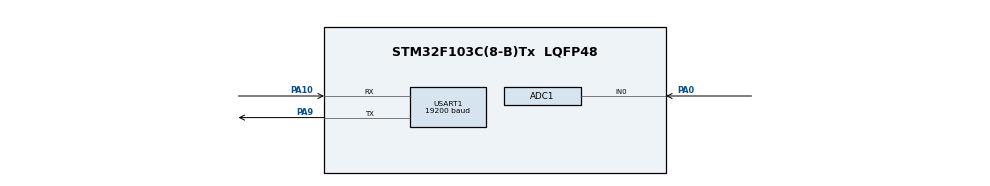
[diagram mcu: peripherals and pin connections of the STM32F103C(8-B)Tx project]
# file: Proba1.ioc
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ADC1.Channel-0\#ChannelRegularConversion=ADC_CHANNEL_0
ADC1.ExternalTrigConv=ADC_EXTERNALTRIGCONV_T3_TRGO
ADC1.NbrOfConversion=1
ADC1.NbrOfConversionFlag=1
ADC1.Rank-0\#ChannelRegularConversion=1
ADC1.SamplingTime-0\#ChannelRegularConversion=ADC_SAMPLETIME_1CYCLE_5
ADC1.master=1
FREERTOS.Mutexes01=myMutex01,Dynamic,NULL
FREERTOS.Queues01=myQueue01,32,int16_t,0,Dynamic,NULL,NULL
FREERTOS.Tasks01=Task1,0,128,ADCValue,Default,NULL,Dynamic,NULL,NULL;Task2,0,128,UARTTransmit,Default,NULL,Dynamic,NULL,NULL
FREERTOS.configUSE_NEWLIB_REENTRANT=1
Mcu.Family=STM32F1
Mcu.Name=STM32F103C(8-B)Tx
Mcu.Package=LQFP48
NVIC.ADC1_2_IRQn=true\:5\:0\:false\:false\:true\:true\:true\:true\:true
NVIC.PriorityGroup=NVIC_PRIORITYGROUP_4
NVIC.TIM1_UP_IRQn=true\:15\:0\:false\:false\:true\:false\:false\:true\:true
NVIC.TimeBase=TIM1_UP_IRQn
NVIC.TimeBaseIP=TIM1
NVIC.USART1_IRQn=true\:5\:0\:false\:false\:true\:true\:true\:true\:true
PA0-WKUP.Signal=ADCx_IN0
PA10.Mode=Asynchronous
PA10.Signal=USART1_RX
PA9.Mode=Asynchronous
PA9.Signal=USART1_TX
ProjectManager.HeapSize=0x200
ProjectManager.StackSize=0x400
ProjectManager.TargetToolchain=STM32CubeIDE
RCC.APB1Freq_Value=8000000
RCC.APB2Freq_Value=8000000
SH.ADCx_IN0.0=ADC1_IN0,IN0
TIM3.Period=65000
TIM3.Prescaler=64
TIM3.TIM_MasterOutputTrigger=TIM_TRGO_UPDATE
USART1.BaudRate=19200
USART1.VirtualMode=VM_ASYNC
VP_FREERTOS_VS_CMSIS_V1.Mode=CMSIS_V1
VP_SYS_VS_tim1.Mode=TIM1
VP_TIM3_VS_ClockSourceINT.Mode=Internal
board=custom

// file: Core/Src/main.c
/* USER CODE BEGIN Header */
/**
  ******************************************************************************
  * @file           : main.c
  * @brief          : Main program body
  ******************************************************************************
  * @attention
  *
  * Copyright (c) 2022 STMicroelectronics.
  * All rights reserved.
  *
  * This software is licensed under terms that can be found in the LICENSE file
  * in the root directory of this software component.
  * If no LICENSE file comes with this software, it is provided AS-IS.
  *
  ******************************************************************************
  */
/* USER CODE END Header */
#include "main.h"
#include "cmsis_os.h"

/* USER CODE BEGIN Includes */
#include "string.h"
/* USER CODE END Includes */

ADC_HandleTypeDef hadc1;

TIM_HandleTypeDef htim3;

UART_HandleTypeDef huart1;

osThreadId Task1Handle;
osThreadId Task2Handle;
osMessageQId myQueue01Handle;
osMutexId myMutex01Handle;

void SystemClock_Config(void);
static void MX_GPIO_Init(void);
static void MX_USART1_UART_Init(void);
static void MX_ADC1_Init(void);
static void MX_TIM3_Init(void);
void ADCValue(void const * argument);
void UARTTransmit(void const * argument);

int main(void)
{

  /* MCU Configuration--------------------------------------------------------*/

  /* Reset of all peripherals, Initializes the Flash interface and the Systick. */
  HAL_Init();

  /* Configure the system clock */
  SystemClock_Config();

  /* Initialize all configured peripherals */
  MX_GPIO_Init();
  MX_USART1_UART_Init();
  MX_ADC1_Init();
  MX_TIM3_Init();
  /* USER CODE BEGIN 2 */

  HAL_ADCEx_Calibration_Start(&hadc1); // On calibration ADC
  HAL_ADC_Start_IT(&hadc1);            // On ADC
  HAL_TIM_Base_Start(&htim3);          // On TIM3

  /* USER CODE END 2 */

  /* Create the mutex(es) */
  /* definition and creation of myMutex01 */
  osMutexDef(myMutex01);
  myMutex01Handle = osMutexCreate(osMutex(myMutex01));

  /* Create the queue(s) */
  /* definition and creation of myQueue01 */
  osMessageQDef(myQueue01, 32, int16_t);
  myQueue01Handle = osMessageCreate(osMessageQ(myQueue01), NULL);

  /* Create the thread(s) */
  /* definition and creation of Task1 */
  osThreadDef(Task1, ADCValue, osPriorityNormal, 0, 128);
  Task1Handle = osThreadCreate(osThread(Task1), NULL);

  /* definition and creation of Task2 */
  osThreadDef(Task2, UARTTransmit, osPriorityNormal, 0, 128);
  Task2Handle = osThreadCreate(osThread(Task2), NULL);

  /* Start scheduler */
  osKernelStart();

  /* We should never get here as control is now taken by the scheduler */
  /* Infinite loop */
  while (1)
  {

  }
}

void SystemClock_Config(void)
{
  RCC_OscInitTypeDef RCC_OscInitStruct = {0};
  RCC_ClkInitTypeDef RCC_ClkInitStruct = {0};
  RCC_PeriphCLKInitTypeDef PeriphClkInit = {0};

  /** Initializes the RCC Oscillators according to the specified parameters
  * in the RCC_OscInitTypeDef structure.
  */
  RCC_OscInitStruct.OscillatorType = RCC_OSCILLATORTYPE_HSI;
  RCC_OscInitStruct.HSIState = RCC_HSI_ON;
  RCC_OscInitStruct.HSICalibrationValue = RCC_HSICALIBRATION_DEFAULT;
  RCC_OscInitStruct.PLL.PLLState = RCC_PLL_NONE;
  if (HAL_RCC_OscConfig(&RCC_OscInitStruct) != HAL_OK)
  {
    Error_Handler();
  }

  /** Initializes the CPU, AHB and APB buses clocks
  */
  RCC_ClkInitStruct.ClockType = RCC_CLOCKTYPE_HCLK|RCC_CLOCKTYPE_SYSCLK
                              |RCC_CLOCKTYPE_PCLK1|RCC_CLOCKTYPE_PCLK2;
  RCC_ClkInitStruct.SYSCLKSource = RCC_SYSCLKSOURCE_HSI;
  RCC_ClkInitStruct.AHBCLKDivider = RCC_SYSCLK_DIV1;
  RCC_ClkInitStruct.APB1CLKDivider = RCC_HCLK_DIV1;
  RCC_ClkInitStruct.APB2CLKDivider = RCC_HCLK_DIV1;

  if (HAL_RCC_ClockConfig(&RCC_ClkInitStruct, FLASH_LATENCY_0) != HAL_OK)
  {
    Error_Handler();
  }
  PeriphClkInit.PeriphClockSelection = RCC_PERIPHCLK_ADC;
  PeriphClkInit.AdcClockSelection = RCC_ADCPCLK2_DIV2;
  if (HAL_RCCEx_PeriphCLKConfig(&PeriphClkInit) != HAL_OK)
  {
    Error_Handler();
  }
}

static void MX_ADC1_Init(void)
{

  ADC_ChannelConfTypeDef sConfig = {0};

  /** Common config
  */
  hadc1.Instance = ADC1;
  hadc1.Init.ScanConvMode = ADC_SCAN_DISABLE;
  hadc1.Init.ContinuousConvMode = DISABLE;
  hadc1.Init.DiscontinuousConvMode = DISABLE;
  hadc1.Init.ExternalTrigConv = ADC_EXTERNALTRIGCONV_T3_TRGO;
  hadc1.Init.DataAlign = ADC_DATAALIGN_RIGHT;
  hadc1.Init.NbrOfConversion = 1;
  if (HAL_ADC_Init(&hadc1) != HAL_OK)
  {
    Error_Handler();
  }

  /** Configure Regular Channel
  */
  sConfig.Channel = ADC_CHANNEL_0;
  sConfig.Rank = ADC_REGULAR_RANK_1;
  sConfig.SamplingTime = ADC_SAMPLETIME_1CYCLE_5;
  if (HAL_ADC_ConfigChannel(&hadc1, &sConfig) != HAL_OK)
  {
    Error_Handler();
  }

}

static void MX_TIM3_Init(void)
{

  TIM_ClockConfigTypeDef sClockSourceConfig = {0};
  TIM_MasterConfigTypeDef sMasterConfig = {0};

  htim3.Instance = TIM3;
  htim3.Init.Prescaler = 64;
  htim3.Init.CounterMode = TIM_COUNTERMODE_UP;
  htim3.Init.Period = 65000;
  htim3.Init.ClockDivision = TIM_CLOCKDIVISION_DIV1;
  htim3.Init.AutoReloadPreload = TIM_AUTORELOAD_PRELOAD_DISABLE;
  if (HAL_TIM_Base_Init(&htim3) != HAL_OK)
  {
    Error_Handler();
  }
  sClockSourceConfig.ClockSource = TIM_CLOCKSOURCE_INTERNAL;
  if (HAL_TIM_ConfigClockSource(&htim3, &sClockSourceConfig) != HAL_OK)
  {
    Error_Handler();
  }
  sMasterConfig.MasterOutputTrigger = TIM_TRGO_UPDATE;
  sMasterConfig.MasterSlaveMode = TIM_MASTERSLAVEMODE_DISABLE;
  if (HAL_TIMEx_MasterConfigSynchronization(&htim3, &sMasterConfig) != HAL_OK)
  {
    Error_Handler();
  }

}

static void MX_USART1_UART_Init(void)
{

  huart1.Instance = USART1;
  huart1.Init.BaudRate = 19200;
  huart1.Init.WordLength = UART_WORDLENGTH_8B;
  huart1.Init.StopBits = UART_STOPBITS_1;
  huart1.Init.Parity = UART_PARITY_NONE;
  huart1.Init.Mode = UART_MODE_TX_RX;
  huart1.Init.HwFlowCtl = UART_HWCONTROL_NONE;
  huart1.Init.OverSampling = UART_OVERSAMPLING_16;
  if (HAL_UART_Init(&huart1) != HAL_OK)
  {
    Error_Handler();
  }

}

static void MX_GPIO_Init(void)
{

  /* GPIO Ports Clock Enable */
  __HAL_RCC_GPIOA_CLK_ENABLE();

}

void ADCValue(void const * argument)
{
  /* USER CODE BEGIN 5 */
	int16_t adc = 0;
		 /* Infinite loop */
	for(;;)
	{
		if( xSemaphoreTake(myMutex01Handle, portMAX_DELAY) == pdTRUE)
		{
			adc = HAL_ADC_GetValue(&hadc1);
			xQueueSendToBack(myQueue01Handle, &adc, 100);
			xSemaphoreGive(myMutex01Handle);
			osDelay(100);
		}
	}
  /* USER CODE END 5 */
}

void UARTTransmit(void const * argument)
{
  /* USER CODE BEGIN UARTTransmit */
	char Voltage[] = {};
	int16_t VoltTask2;

  /* Infinite loop */
  for(;;)
  {
	  if( xSemaphoreTake(myMutex01Handle, portMAX_DELAY) == pdTRUE)
		{
			xQueueReceive(myQueue01Handle, &VoltTask2, 100);
			snprintf(Voltage, 15, "%d\n", VoltTask2);
			HAL_UART_Transmit(&huart1, Voltage, strlen(Voltage), 100);
			xSemaphoreGive(myMutex01Handle);
			osDelay(100);
		}
  }
  /* USER CODE END UARTTransmit */
}

void HAL_TIM_PeriodElapsedCallback(TIM_HandleTypeDef *htim)
{
  if (htim->Instance == TIM1) {
    HAL_IncTick();
  }
}

void Error_Handler(void)
{
  __disable_irq();
  while (1)
  {
  }
}
